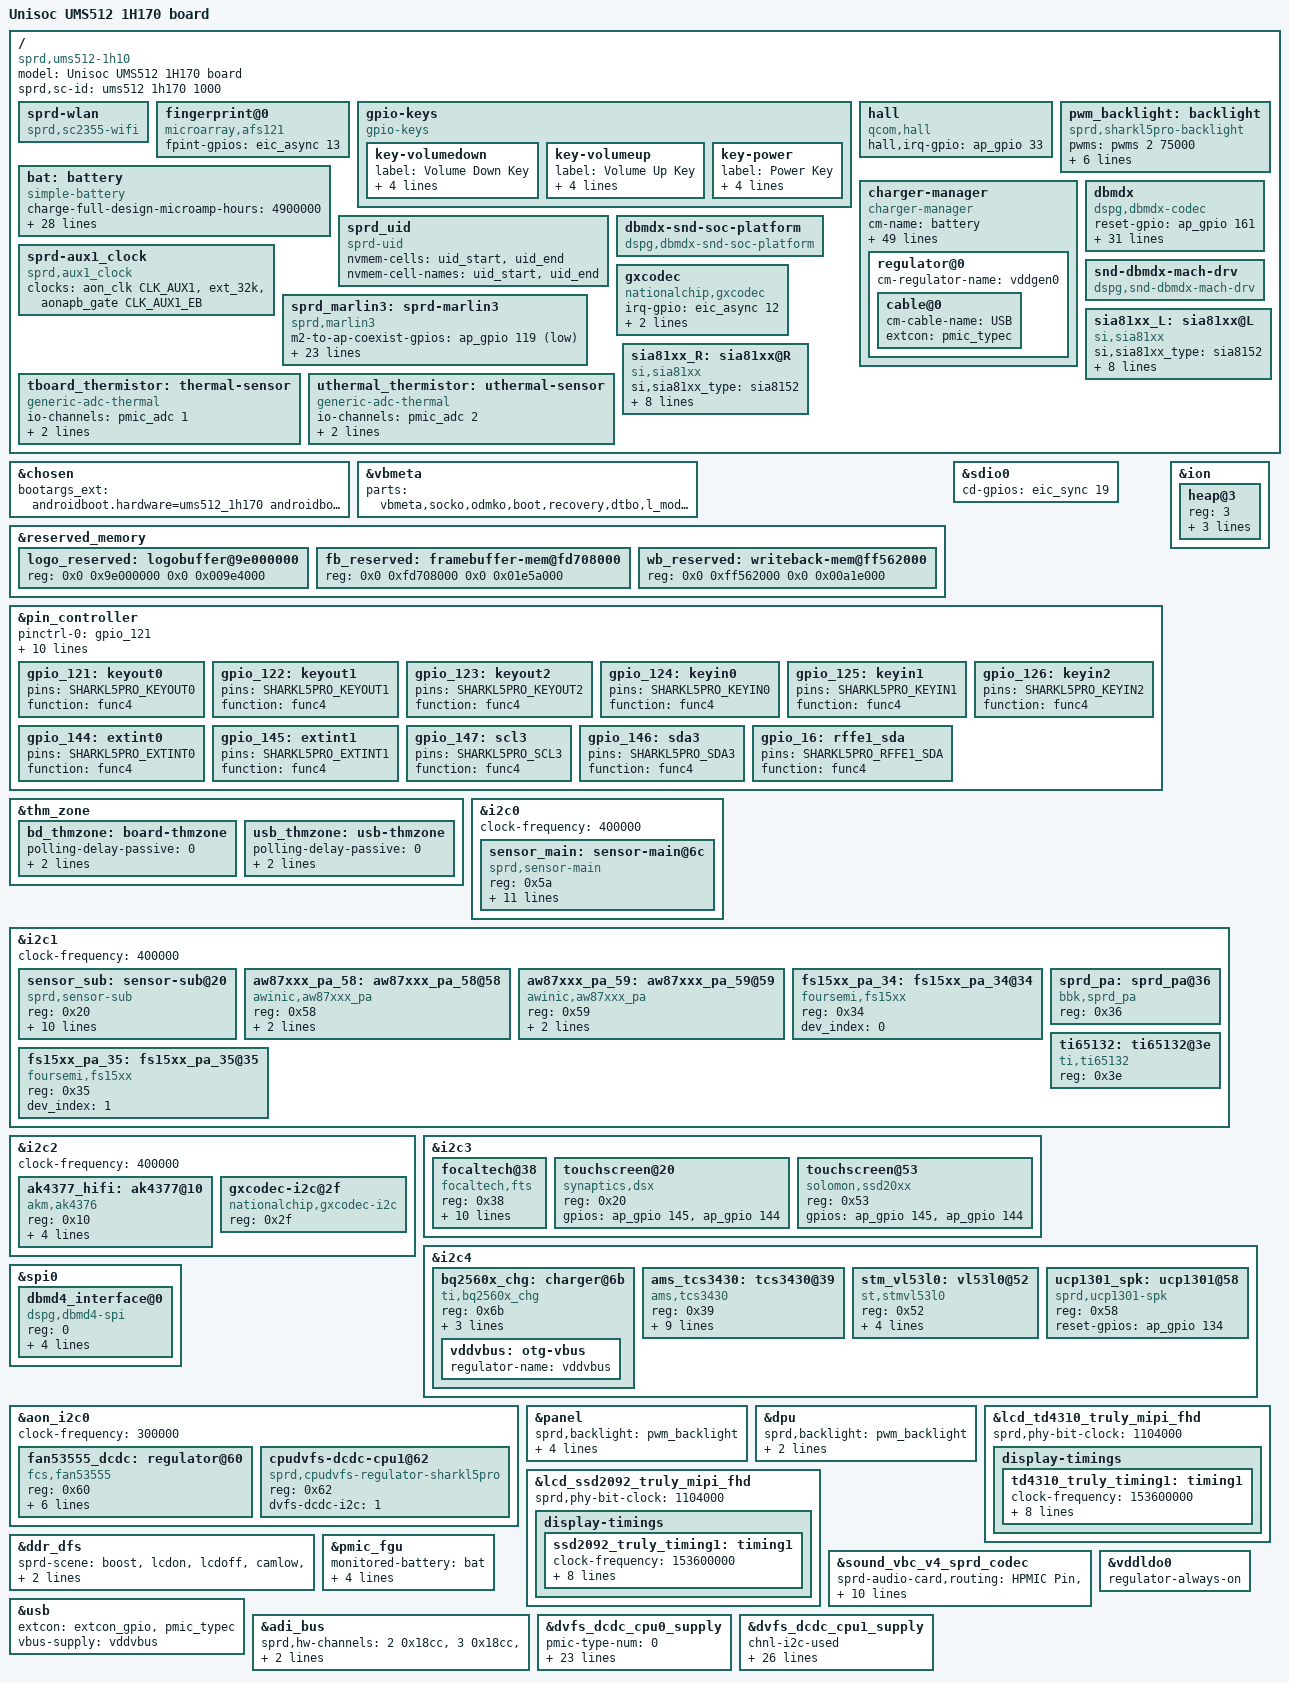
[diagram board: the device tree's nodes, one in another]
/*
 * EEBBK A3 (ums512_1h170) board overlay
 * -------------------------------------
 * Reconstructed from the factory DTBO overlay (dtbo partition, idx 2,
 * sc-id "ums512 1h170 1000") decompiled from the device, adapted to the
 * UNISOC 4.14.193 tree structure (labels per ums512.dtsi / ums512-mach.dtsi).
 * Values (battery, GPIOs, clocks, lcd panels) are verbatim from the factory
 * device tree. Kernel base: android_kernel_realme_ums512 (4.14.193).
 */
/dts-v1/;
/plugin/;

#include <dt-bindings/input/input.h>
#include <dt-bindings/gpio/gpio.h>
#include <dt-bindings/interrupt-controller/arm-gic.h>
#include <dt-bindings/clock/sprd,sharkl5pro-clk.h>
#include <dt-bindings/mfd/sprd,sc2730-regs.h>
#include <dt-bindings/mfd/sprd,sc2730-mask.h>
#include "lcd/lcd_ft8201ab_boe_mipi_fhd_bbk_H170.dtsi"
#include "lcd/lcd_ft8201ab_boe_mipi_fhd_bbk_H170.dtsi"
#include "lcd/lcd_td4310_truly_mipi_fhd.dtsi"
#include "lcd/lcd_ssd2092_truly_mipi_fhd.dtsi"
#include "lcd/lcd_dummy_mipi.dtsi"

/ {

	model = "Unisoc UMS512 1H170 board";
	compatible = "sprd,ums512-1h10";
	sprd,sc-id = "ums512 1h170 1000";

	fragment {
		target-path = "/";
		__overlay__ {
			sprd-wlan {
				compatible = "sprd,sc2355-wifi";
			};

			fingerprint@0 {
				compatible = "microarray,afs121";
				fpint-gpios = <&eic_async 13 0>;
			};

			gpio-keys {
				compatible = "gpio-keys";

				key-volumedown {
					label = "Volume Down Key";
					linux,code = <KEY_VOLUMEDOWN>;
					gpios = <&ap_gpio 124 GPIO_ACTIVE_LOW>;
					debounce-interval = <2>;
					wakeup-source;
				};

				key-volumeup {
					label = "Volume Up Key";
					linux,code = <KEY_VOLUMEUP>;
					gpios = <&pmic_eic 4 GPIO_ACTIVE_HIGH>;
					debounce-interval = <2>;
					wakeup-source;
				};

				key-power {
					label = "Power Key";
					linux,code = <KEY_POWER>;
					gpios = <&pmic_eic 1 GPIO_ACTIVE_LOW>;
					debounce-interval = <2>;
					wakeup-source;
				};
			};

			hall {
				compatible = "qcom,hall";
				hall,irq-gpio = <&ap_gpio 33 2>;
			};

			pwm_backlight: backlight {
				compatible = "sprd,sharkl5pro-backlight";
				pwms = <&pwms 2 75000>;
				pwm-names = "backlight";
				sprd,max-brightness-level = <880>;
				default-brightness-level = <250>;
				sprd,brightness-scale = <1023>;
				brightness-levels = <
							  0   3   4   5   6   7
					  8   9  10  11  12  13  14  15  16  17
					 18  19  20  21  22  23  24  25  26  27
					 28  29  31  33  35  37  39  41  43  45
					 46  48  50  52  54  56  58  60  62  64
					 66  68  70  72  74  76  78  80  82  84
					 86  88  90  92  94  96  98 100 102 104
					106 108 110 112 114 116 118 120 122 124
					126 128 130 132 134 136 138 140 142 144
					146 148 150 152 154 156 158 160 162 164
					166 169 172 175 178 181 184 187 190 193
					196 199 202 205 208 211 214 217 220 223
					226 229 232 235 238 241 244 247 250 253
					256 259 262 265 268 271 274 277 280 283
					286 290 294 298 302 306 310 314 318 322
					326 330 334 338 342 346 350 354 358 362
					366 370 374 378 382 386 390 394 398 402
					406 410 414 418 422 426 430 434 438 442
					446 451 456 461 466 471 476 481 486 491
					496 501 506 511 516 521 526 531 536 541
					546 551 556 561 566 571 576 581 586 591
					596 601 606 611 616 621 626 631 636 641
					646 652 658 664 670 676 682 688 694 700
					706 712 718 724 730 736 742 748 754 760
					766 772 778 784 790 796 802 808 814 820
					826 832 838 844 850 856 862 868 874 880
				>;
			};

			bat: battery {
				compatible = "simple-battery";
				charge-full-design-microamp-hours = <4900000>;
				charge-term-current-microamp = <240000>;
				constant_charge_voltage_max_microvolt = <4423000>;
				factory-internal-resistance-micro-ohms = <134000>;
				voltage-min-design-microvolt = <3480000>;
				ocv-capacity-celsius = <25>;
				ocv-capacity-table-0 = <4386000 100>, <4329000 95>, <4274000 90>,
							<4217000 85>, <4160000 80>, <4106000 75>,
							<4055000 70>, <4008000 65>, <3964000 60>,
							<3905000 55>, <3866000 50>, <3840000 45>,
							<3818000 40>, <3800000 35>, <3784000 30>,
							<3766000 25>, <3744000 20>, <3719000 15>,
							<3690000 10>, <3679000 5>, <3460000 0>;
				voltage-temp-table = <1092500 800>, <984400 850>, <877900 900>,
						  <775600 950>, <679400 1000>, <591100 1050>,
						  <511400 1100>, <440700 1150>, <378500 1200>,
						  <324500 1250>, <278000 1300>, <238000 1350>,
						  <204000 1400>, <175000 1450>, <150300 1500>,
						  <129400 1550>, <111600 1600>, <96500 1650>;
				capacity-temp-table = <50 98>, <25 100>, <10 92>, <0 74>, <(-10) 65>, <(-20) 55>;
				resistance-temp-table = <50 74>, <25 100>, <10 168>, <0 380>, <(-10) 539>, <(-20) 750>;
				charge-sdp-current-microamp = <500000 500000>;
				charge-dcp-current-microamp = <2160000 2000000>;
				charge-cdp-current-microamp = <1150000 1150000>;
				charge-unknown-current-microamp = <2160000 2000000>;
			};

			charger-manager {
				compatible = "charger-manager";
				cm-name = "battery";
				cm-poll-mode = <2>;
				cm-poll-interval = <2000>;
				cm-battery-stat = <2>;

				cm-fullbatt-vchkdrop-ms = <30000>;
				cm-fullbatt-vchkdrop-volt = <60000>;
				cm-fullbatt-voltage = <4377750>;
				cm-fullbatt-current = <240000>;
				cm-fullbatt-capacity = <100>;

				cm-num-chargers = <1>;
				cm-chargers = "bq2560x_charger";
				cm-fuel-gauge = "sc27xx-fgu";

				/* in deci centigrade */
				cm-battery-cold = <200>;
				cm-battery-cold-in-minus;
				cm-battery-hot = <800>;
				cm-battery-temp-diff = <100>;

				/* Allow charging for 18hr */
				cm-charging-max = <64800000>;
				/* recovery charging after stop charging 45min */
				cm-discharging-max = <2700000>;

				/* the interval to feed charger watchdog */
				cm-wdt-interval = <60>;

				/* drop voltage in microVolts to allow shutdown */
				cm-shutdown-voltage = <3380000>;

				/* when 99% of the time is exceeded, it will be forced to 100% */
				cm-tickle-time-out = <1500>;

				/* how much time to allow capacity change */
				cm-one-cap-time = <30>;
				cm-thermal-zone = "board-thmzone";
				/* when the safe charging voltage is exceeded, stop charging */
				cm-charge-voltage-max = <6500000>;
				/* drop voltage in microVolts to restart charging */
				cm-charge-voltage-drop = <700000>;
				cm-dcp-jeita-temp-table = <1000 1010 0 4423000>, <1100 1110 1380000 4423000>,
					<1200 1210 1980000 4423000>, <1450 1440 2160000 4423000>,
					<1550 1540 1440000 4103000>;
				cm-sdp-jeita-temp-table = <1000 1010 0 4423000>, <1100 1110 500000 4423000>,
					<1200 1210 500000 4423000>, <1450 1440 500000 4423000>,
					<1550 1540 500000 4103000>;
				cm-cdp-jeita-temp-table = <1000 1010 0 4423000>, <1100 1110 1200000 4423000>,
					<1200 1210 1200000 4423000>, <1450 1440 1200000 4423000>,
					<1550 1540 1200000 4103000>;
				cm-unknown-jeita-temp-table = <1000 1010 0 4423000>, <1100 1110 1380000 4423000>,
					<1200 1210 1980000 4423000>, <1450 1440 2160000 4423000>,
					<1550 1540 1440000 4103000>;

				monitored-battery = <&bat>;
				fgu-capacity-track;

				cm-cap-remap-table = <1 2 3>, <2 3 2>, <98 99 2>, <99 100 3>;

				regulator@0 {
					cm-regulator-name = "vddgen0";
					cable@0 {
						cm-cable-name = "USB";
						extcon = <&pmic_typec>;
					};
				};
			};

			sprd_uid {
				compatible = "sprd-uid";
				nvmem-cells = <&uid_start>, <&uid_end>;
				nvmem-cell-names = "uid_start", "uid_end";
			};

			sprd-aux1_clock {
				compatible = "sprd,aux1_clock";
				clock-names = "clk_32k", "source", "enable";
				clocks = <&aon_clk CLK_AUX1>, <&ext_32k>,
					 <&aonapb_gate CLK_AUX1_EB>;
			};

			dbmdx {
				status = "okay";
				compatible = "dspg,dbmdx-codec";
				reset-gpio = <&ap_gpio 161 0>;
				sv-gpio = <&eic_async 12 0>;
				wakeup-gpio = <&ap_gpio 52 0>;
				auto_buffering = <1>;
				multi-interface-support = <1>;
				cd-interfaces = <7>;
				va-interfaces = <0 0 0 0>;
				feature-va;
				va-firmware-name = "dbmd4_va_fw.bin";
				va-config = <0x80000000 0x80000000 0x80290020 0x802210c0
					0x80330056 0x80091400 0x80158989 0x801b0020
					0x80230000 0x801a0011 0x80105000 0x8aab0040
					0x80410001 0x80000000 0x80000000 0x80000000>;
				va-speeds = <0 0x70800 0 0xea600 0 0x1e8480 0 0x493e00
					0 0x2dc6c0 0 0x493e00>;
				va-mic-config = <0xf051 0x1044 0x08>;
				va-mic-mode = <4>;
				analog_mic_analog_gain = <5>;
				master-clk-rate = <0x8000>;
				firmware_id = <0xdbd4>;
				use_gpio_for_wakeup = <1>;
				wakeup_set_value = <0>;
				auto_detection = <1>;
				detection_buffer_channels = <0>;
				min_samples_chunk_size = <0x80>;
				pcm_streaming_mode = <1>;
				boot_options = <0x200>;
				amodel_options = <4>;
				send_uevent_on_detection = <1>;
				send_uevent_after_buffering = <0>;
				detection_after_buffering = <0>;
				va_backlog_length = <0x6a4>;
				va_advanced_options = <0x1d>;
				va_passphrase_margins = <0x12c0000>;
			};

			dbmdx-snd-soc-platform {
				compatible = "dspg,dbmdx-snd-soc-platform";
			};

			snd-dbmdx-mach-drv {
				compatible = "dspg,snd-dbmdx-mach-drv";
			};

			gxcodec {
				compatible = "nationalchip,gxcodec";
				irq-gpio = <&eic_async 12 0>;
				power-gpio = <&ap_gpio 161 0>;
				vddcore-supply = <&vddrf1v25>;
			};

			sprd_marlin3: sprd-marlin3 {
				compatible = "sprd,marlin3";
				m2-to-ap-coexist-gpios = <&ap_gpio 119 GPIO_ACTIVE_LOW>;
				m2-wakeup-ap-gpios = <&ap_gpio 32 GPIO_ACTIVE_LOW>;
				permit-ap-send-gpios = <&ap_gpio 121 GPIO_ACTIVE_LOW>;
				reset-gpios = <&ap_gpio 97 GPIO_ACTIVE_LOW>;
				enable-gpios = <&ap_gpio 143 GPIO_ACTIVE_LOW>;
				m2-to-ap-irq-gpios = <&ap_gpio 96 GPIO_ACTIVE_LOW>;
				avdd12-supply = <&vddwcn>;
				avdd33-supply = <&vddwifipa>;
				dcxo18-supply = <&vddsim2>;

				clock-names = "clk_32k","source","enable";
				clocks = <&aon_clk CLK_AUX0>,
					 <&ext_32k>,
					 <&aonapb_gate CLK_AUX0_EB>;

				sdhci-name = <&sdio1>;
				sprd,btwf-file-name = "/dev/block/platform/soc/soc:ap-apb/71400000.sdio/by-name/wcnmodem";
				sprd,gnss-file-name = "/dev/block/platform/soc/soc:ap-apb/71400000.sdio/by-name/gnssmodem";
				adma-tx;
				adma-rx;
				/*
				 * bound parameter:
				 * [0]:addr offset, [1]:mask, [2]:unboundval, [3]:boundval
				 */
				avdd12-parent-bound-chip = <REG_ANA_SLP_DCDC_PD_CTRL MASK_ANA_SLP_DCDCGEN1_PD_EN 0x0 MASK_ANA_SLP_DCDCGEN1_PD_EN>;
				avdd12-bound-wbreq = <REG_ANA_LDO_XTL_EN10 MASK_ANA_LDO_VDDWCN_EXT_XTL3_EN 0x0 MASK_ANA_LDO_VDDWCN_EXT_XTL3_EN>;
				avdd33-bound-wbreq = <REG_ANA_LDO_XTL_EN11 MASK_ANA_LDO_VDDWIFIPA_EXT_XTL3_EN 0x0 MASK_ANA_LDO_VDDWIFIPA_EXT_XTL3_EN>;
			};

			tboard_thermistor: thermal-sensor {
				compatible = "generic-adc-thermal";
				#thermal-sensor-cells = <0>;
				io-channels = <&pmic_adc 1>;
				io-channel-names = "sensor-channel";
				temperature-lookup-table = <    (-39742) 1260
								(-29777) 1213
								(-19480) 1146
								(-4679) 1005
								10110 824
								24805 632
								44922 409
								54903 322
								64895 252
								74884 197
								84883 154
								94883 121
								104880 98
								114889 76
								124872 61 >;
			};

			uthermal_thermistor: uthermal-sensor {
				compatible = "generic-adc-thermal";
				#thermal-sensor-cells = <0>;
				io-channels = <&pmic_adc 2>;
				io-channel-names = "sensor-channel";
				temperature-lookup-table = <    (-39742) 1330
								(-29777) 1327
								(-19480) 1321
								(-4679) 1302
								10110 1266
								24805 1200
								44922 1049
								54903 946
								64895 830
								74884 709
								84883 592
								94883 485
								104880 391
								114889 313
								124872 249 >;
			};

			/* smart speaker amps (SIA8152) */
			sia81xx_L: sia81xx@L {
				compatible = "si,sia81xx";
				si,sia81xx_type = "sia8152";
				si,sia81xx_disable_pin = <1>;
				timer_task_hdl = <0>;
				channel_num = <0>;
				owi_mode = <1>;
				en_x_filter = <0>;
				en_dynamic_updata_vdd = <1>;
				en_dynamic_updata_pvdd = <1>;
				dynamic_updata_vdd_port = <2>;
			};

			sia81xx_R: sia81xx@R {
				compatible = "si,sia81xx";
				si,sia81xx_type = "sia8152";
				si,sia81xx_disable_pin = <1>;
				timer_task_hdl = <0>;
				channel_num = <1>;
				owi_mode = <1>;
				en_x_filter = <0>;
				en_dynamic_updata_vdd = <1>;
				en_dynamic_updata_pvdd = <1>;
				dynamic_updata_vdd_port = <2>;
			};
		};
	};
};

&chosen {
	bootargs_ext = "androidboot.hardware=ums512_1h170 androidboot.dtbo_idx=0";
};

&vbmeta {
	parts = "vbmeta,socko,odmko,boot,recovery,dtbo,l_modem,pm_sys,l_ldsp,l_gdsp,l_agdsp,l_cdsp";
};

&reserved_memory {

	logo_reserved: logobuffer@9e000000{
		reg = <0x0 0x9e000000 0x0 0x009e4000>;
	};

	fb_reserved: framebuffer-mem@fd708000 {
		reg = <0x0 0xfd708000 0x0 0x01e5a000>;
	};

	wb_reserved: writeback-mem@ff562000 {
		reg = <0x0 0xff562000 0x0 0x00a1e000>;
	};

};

&sdio0 {
	cd-gpios = <&eic_sync 19 GPIO_ACTIVE_HIGH>;
};

&pin_controller {
	pinctrl-names =
	/* keyout0 ~ keyout2 */
	"gpio_121", "gpio_122", "gpio_123",
	/* keyin0 ~ keyin2 */
	"gpio_124", "gpio_125", "gpio_126",
	/* extint0, extint1, scl3, sda3, sda */
	"gpio_144", "gpio_145", "gpio_146", "gpio_147", "gpio_16";

	pinctrl-0 = <&gpio_121>;
	pinctrl-1 = <&gpio_122>;
	pinctrl-2 = <&gpio_123>;
	pinctrl-3 = <&gpio_124>;
	pinctrl-4 = <&gpio_125>;
	pinctrl-5 = <&gpio_126>;
	pinctrl-6 = <&gpio_144>;
	pinctrl-7 = <&gpio_145>;
	pinctrl-8 = <&gpio_146>;
	pinctrl-9 = <&gpio_147>;
	pinctrl-10 = <&gpio_16>;

	gpio_121: keyout0 {
		pins = "SHARKL5PRO_KEYOUT0";
		function = "func4";
	};

	gpio_122: keyout1 {
		pins = "SHARKL5PRO_KEYOUT1";
		function = "func4";
	};

	gpio_123: keyout2 {
		pins = "SHARKL5PRO_KEYOUT2";
		function = "func4";
	};

	gpio_124: keyin0 {
		pins = "SHARKL5PRO_KEYIN0";
		function = "func4";
	};

	gpio_125: keyin1 {
		pins = "SHARKL5PRO_KEYIN1";
		function = "func4";
	};

	gpio_126: keyin2 {
		pins = "SHARKL5PRO_KEYIN2";
		function = "func4";
	};

	gpio_144: extint0 {
		pins = "SHARKL5PRO_EXTINT0";
		function = "func4";
	};

	gpio_145: extint1 {
		pins = "SHARKL5PRO_EXTINT1";
		function = "func4";
	};

	gpio_147: scl3 {
		pins = "SHARKL5PRO_SCL3";
		function = "func4";
	};

	gpio_146: sda3 {
		pins = "SHARKL5PRO_SDA3";
		function = "func4";
	};

	gpio_16: rffe1_sda {
		pins = "SHARKL5PRO_RFFE1_SDA";
		function = "func4";
	};
};

&thm_zone {
	bd_thmzone: board-thmzone {
		polling-delay-passive = <0>;
		polling-delay = <0>;
		thermal-sensors = <&tboard_thermistor>;
	};

	usb_thmzone: usb-thmzone {
		polling-delay-passive = <0>;
		polling-delay = <0>;
		thermal-sensors = <&uthermal_thermistor>;
	};
};

&ion {
	heap@3 {
		reg = <3>;
		label = "carveout_fb";
		type = <2>;
		memory-region = <&fb_reserved>;
	};
};

&i2c0 {
	status = "okay";
	clock-frequency = <400000>;

	sensor_main: sensor-main@6c {
		compatible = "sprd,sensor-main";
		reg = <0x5a>;
		clock-names = "clk_src","sensor_eb",
			"clk_96m","clk_76m8",
			"clk_48m","clk_26m";
		clocks = <&mm_clk CLK_SENSOR0>,<&mm_gate CLK_MM_SENSOR0_EB>,
				<&pll2 CLK_TWPLL_96M>,<&pll2 CLK_TWPLL_76M8>,
				<&pll2 CLK_TWPLL_48M>,<&ext_26m>;
		vddio-supply = <&vddcamio>;
		vddcama-supply = <&vddcama0>;
		vddcamd-supply = <&vddcamd1>;
		vddcammot-supply = <&vddcammot>;
		reset-gpios = <&ap_gpio 45 0>;
		sprd,phyid = <0>;
		csi = <&csi0>;
	};
};

&i2c1 {
	status = "okay";
	clock-frequency = <400000>;

	sensor_sub: sensor-sub@20 {
		compatible = "sprd,sensor-sub";
		reg = <0x20>;
		clock-names = "clk_src","sensor_eb",
			"clk_96m","clk_76m8",
			"clk_48m","clk_26m";
		clocks = <&mm_clk CLK_SENSOR1>,<&mm_gate CLK_MM_SENSOR1_EB>,
				<&pll2 CLK_TWPLL_96M>,<&pll2 CLK_TWPLL_76M8>,
				<&pll2 CLK_TWPLL_48M>,<&ext_26m>;
		vddio-supply = <&vddcamio>;
		vddcama-supply = <&vddcama0>;
		vddcamd-supply = <&vddcamd0>;
		reset-gpios = <&ap_gpio 41 0>;
		sprd,phyid = <1>;
		csi = <&csi0>;
	};

	/* smart speaker amps — L/R (AW87xxx / SIA8152), on i2c1 per factory DT */
	aw87xxx_pa_58: aw87xxx_pa_58@58 {
		compatible = "awinic,aw87xxx_pa";
		reg = <0x58>;
		si,sia81xx-dev = <&sia81xx_L>;
		dev_index = <0>;
		status = "okay";
	};

	aw87xxx_pa_59: aw87xxx_pa_59@59 {
		compatible = "awinic,aw87xxx_pa";
		reg = <0x59>;
		si,sia81xx-dev = <&sia81xx_R>;
		dev_index = <1>;
		status = "okay";
	};

	fs15xx_pa_34: fs15xx_pa_34@34 {
		compatible = "foursemi,fs15xx";
		reg = <0x34>;
		dev_index = <0>;
		status = "okay";
	};

	fs15xx_pa_35: fs15xx_pa_35@35 {
		compatible = "foursemi,fs15xx";
		reg = <0x35>;
		dev_index = <1>;
		status = "okay";
	};

	sprd_pa: sprd_pa@36 {
		compatible = "bbk,sprd_pa";
		reg = <0x36>;
		status = "okay";
	};

	ti65132: ti65132@3e {
		compatible = "ti,ti65132";
		reg = <0x3e>;
	};
};

&i2c2 {
	status = "okay";
	clock-frequency = <400000>;

	ak4377_hifi: ak4377@10 {
		compatible = "akm,ak4376";
		reg = <0x10>;
		#sound-dai-cells = <1>;
		sprd,vddldo1-voltage = <1800000>;
		ak4377,pdn-gpio = <&ap_gpio 116 GPIO_ACTIVE_HIGH>;

		clock-names = "clk_48M", "source", "enable";
		clocks = <&aon_clk CLK_AUX1>,
			 <&pll2 CLK_TWPLL_19M2>,
			 <&aonapb_gate CLK_AUX1_EB>;
	};

	gxcodec-i2c@2f {
		compatible = "nationalchip,gxcodec-i2c";
		reg = <0x2f>;
	};

};

&i2c3 {
	status = "okay";

	/* FocalTech FTS — the active touch controller on this board (i2c-3 @ 0x38) */
	focaltech@38 {
		compatible = "focaltech,fts";
		reg = <0x38>;
		status = "okay";
		focaltech,irq-gpio = <&eic_async 0 0>;
		focaltech,irq-flags = <2>;
		focaltech,reset-gpio = <&ap_gpio 145 0>;
		focaltech,max-touch-number = <10>;
		focaltech,display-coords = <0 0 1279 1751>;
		tpd-filter-enable = <0>;
		tpd-filter-pixel-density = <161>;
		tpd-filter-custom-prameters = <0 0 0 0 0 0 0 0 0 0 0 0>;
		tpd-filter-custom-speed = <0 0 0>;
	};

	/* alternate touch drivers present on the same bus (hardware absent) */
	touchscreen@20 {
		compatible = "synaptics,dsx";
		reg = <0x20>;
		gpios = <&ap_gpio 145 GPIO_ACTIVE_HIGH
			&ap_gpio 144 GPIO_ACTIVE_HIGH>;
	};

	touchscreen@53 {
		compatible = "solomon,ssd20xx";
		reg = <0x53>;
		gpios = <&ap_gpio 145 GPIO_ACTIVE_HIGH
			&ap_gpio 144 GPIO_ACTIVE_HIGH>;
	};
};

&i2c4 {
	status = "okay";

	bq2560x_chg: charger@6b {
		compatible = "ti,bq2560x_chg";
		reg = <0x6b>;
		phys = <&hsphy>;
		monitored-battery = <&bat>;
		extcon = <&extcon_gpio>;
		vddvbus: otg-vbus {
			regulator-name = "vddvbus";
		};
	};

	ams_tcs3430: tcs3430@39 {
		compatible = "ams,tcs3430";
		reg = <0x39>;
		als_name = "ams_als";
		persist = <0>;
		als_time_ms = <100>;
		als_gain = <64>;
		int_config = <0>;
		als_can_wake = <1>;
		irq_gpios = <112>;
		interrupt-parent = <&ap_gpio>;
		interrupts = <112 IRQ_TYPE_LEVEL_LOW>;
	};

	stm_vl53l0: vl53l0@52 {
		compatible = "st,stmvl53l0";
		reg = <0x52>;
		reset_gpios = <86>;
		irq_gpios = <87>;
		interrupt-parent = <&ap_gpio>;
		interrupts = <87 IRQ_TYPE_LEVEL_LOW>;
	};

	/* speaker amplifier */
	ucp1301_spk: ucp1301@58 {
		compatible = "sprd,ucp1301-spk";
		reg = <0x58>;
		reset-gpios = <&ap_gpio 134 0>;
		#sound-dai-cells = <1>;
	};
};

&spi0 {
	status = "okay";

	dbmd4_interface@0 {
		compatible = "dspg,dbmd4-spi";
		reg = <0>;
		spi-max-frequency = <12000000>;
		read-chunk-size = <0x2000>;
		write-chunk-size = <0x40000>;
		dma_min_buffer_size = <0>;
	};
};

&aon_i2c0 {
	status = "okay";
	clock-frequency = <300000>;

	fan53555_dcdc: regulator@60 {
		compatible = "fcs,fan53555";
		reg = <0x60>;
		regulator-name = "fan53555";
		regulator-min-microvolt = <600000>;
		regulator-max-microvolt = <1230000>;
		regulator-ramp-delay = <64000>;
		regulator-always-on;
		fcs,suspend-voltage-selector = <1>;
	};

	/* A virtual i2c device */
	cpudvfs-dcdc-cpu1@62{
		compatible = "sprd,cpudvfs-regulator-sharkl5pro";
		reg = <0x62>;
		dvfs-dcdc-i2c = <1>;
	};
};

&panel {
	sprd,backlight = <&pwm_backlight>;
	power-supply = <&vddldo1>;
	avdd-gpio = <&ap_gpio 139 GPIO_ACTIVE_HIGH>;
	avee-gpio = <&ap_gpio 137 GPIO_ACTIVE_HIGH>;
	reset-gpio = <&ap_gpio 50 GPIO_ACTIVE_HIGH>;
};

&dpu {
	sprd,backlight = <&pwm_backlight>;
	sprd,wb-memory = <&wb_reserved>;
	sprd,logo-memory = <&logo_reserved>;
};

&lcd_td4310_truly_mipi_fhd {
	sprd,phy-bit-clock = <1104000>;  /* kbps */

	display-timings {
		td4310_truly_timing1: timing1 {
			clock-frequency = <153600000>;
			hactive = <720>;
			vactive = <1440>;
			hback-porch = <20>;
			hfront-porch = <50>;
			vback-porch = <28>;
			vfront-porch = <4>;
			hsync-len = <2>;
			vsync-len = <2>;
		};
	};
};

&lcd_ssd2092_truly_mipi_fhd {
	sprd,phy-bit-clock = <1104000>;  /* kbps */

	display-timings {
		ssd2092_truly_timing1: timing1 {
			clock-frequency = <153600000>;
			hactive = <720>;
			vactive = <1440>;
			hback-porch = <20>;
			hfront-porch = <20>;
			vback-porch = <43>;
			vfront-porch = <76>;
			hsync-len = <4>;
			vsync-len = <1>;
		};
	};
};

&ddr_dfs {
	sprd-scene = "boost", "lcdon", "lcdoff", "camlow",
		"camhigh", "camveryhigh", "faceid";
	sprd-freq = <1333 768 256 384 512 0xbacd 1333>;
};

&sound_vbc_v4_sprd_codec {
	status = "okay";
	sprd-audio-card,routing =
		"HPMIC Pin", "HP Mic Jack",
		"MIC Pin", "Mic Jack",
		"MIC2 Pin", "Aux Mic Jack",
		"HeadPhone Jack", "HP Pin",
		"Ext Spk", "HP Pin",
		"Ext Spk1", "HP Pin",
		"Ext Spk", "SPK Pin",
		"Ext Spk1", "SPK Pin",
		"Ext Ear", "EAR Pin",
		"Ext Ear", "SPK Pin",
		"Ext Ear", "HP Pin";
	/* external smart PA control (AW87xxx) */
	sprd,spk-ext-pa-info = <0 1 4 0 2 1 4 1>;
	/* SIA81xx integration (driver optional; harmless if absent) */
	si,sia81xx-max-num = <2>;
	si,sia81xx-aux-devs = <&sia81xx_L>, <&sia81xx_R>;
	si,sia81xx-aux-devs-prefix = "SpkrLeft", "SpkrRight";
};

&pmic_fgu {
	monitored-battery = <&bat>;
	sprd,calib-resistance-real = <10000>;
	sprd,calib-resistance-spec = <20000>;
	first-calib-voltage = <3690000>;
	first-calib-capacity = <100>;
};

&usb {
	extcon = <&extcon_gpio>, <&pmic_typec>;
	vbus-supply = <&vddvbus>;
};

&vddldo0 {
	regulator-always-on;
};

&adi_bus {
	sprd,hw-channels = <2 0x18cc>, <3 0x18cc>, <13 0x1854>, <15 0x1874>,
			 <17 0x1844>,<19 0x1844>, <21 0x1864>, <30 0x1820>,
			 <35 0x19b8>, <39 0x19ac>;
};

&dvfs_dcdc_cpu0_supply {
	pmic-type-num = <0>;
	slew-rate = <9375>; /* 9375uV/us */
	top-dvfs-adi-state = <0x70 0 0xf>;
	voltage-grade-num = <7>;
	voltage-grade = <0 0xf0 0xf4 0 0x1ff>,
		<1 0xf0 0xf4 9 0x1ff>,
		<2 0x100 0xf4 18 0x1ff>,
		<3 0x110 0xf8 0 0x1ff>,
		<4 0x120 0xf8 9 0x1ff>,
		<5 0x130 0xf8 18 0x1ff>,
		<6 0x140 0xfc 0 0x1ff>;
	voltage-up-delay = <50 0x58 0 0xffff 0x600>,
		<100 0x58 16 0xffff 0xa00>,
		<150 0x54 0 0xffff 0xf00>,
		<200 0x54 16 0xffff 0x1400>,
		<250 0x50 0 0xffff 0x1900>,
		<300 0x50 16 0xffff 0x1e00>,
		<350 0x110 0 0xffff 0x2300>;
	voltage-down-delay = <50 0x64 0 0xffff 0x600>,
		<100 0x64 16 0xffff 0xa00>,
		<150 0x60 0 0xffff 0xf00>,
		<200 0x60 16 0xffff 0x1400>,
		<250 0x5c 0 0xffff 0x1900>,
		<300 0x5c 16 0xffff 0x1e00>,
		<350 0x114 0 0xffff 0x2300>;
	tuning-latency-us = <0>;
	chnl-in-i2c = <0>;
};

&dvfs_dcdc_cpu1_supply {
	chnl-i2c-used;
	third-pmic-used;
	pmic-type-num = <2>;
	slew-rate = <4000>; /* 4000uV/us */
	supply-type-sel = <0x120 0 1>;
	top-dvfs-i2c-state = <0x9c 4 0xf>;
	voltage-grade-num = <6>;
	voltage-grade = <0 0x0f 0x12c 0 0x7f>,
		<1 0x14 0x12c 7 0x7f>,
		<2 0x19 0x12c 14 0x7f>,
		<3 0x1e 0x12c 21 0x7f>,
		<4 0x23 0x130 0 0x7f>,
		<5 0x28 0x130 7 0x7f>;
	voltage-up-delay = <50 0x84 0 0xffff 0x1600>,
		<100 0x84 16 0xffff 0x1a00>,
		<150 0x80 0 0xffff 0x1f00>,
		<200 0x80 16 0xffff 0x2400>,
		<250 0x7c 0 0xffff 0x2900>,
		<300 0x7c 16 0xffff 0x2e00>,
		<350 0x118 0 0xffff 0x3300>;
	voltage-down-delay = <50 0x90 0 0xffff 0x600>,
		<100 0x90 16 0xffff 0xa00>,
		<150 0x8c 0 0xffff 0xf00>,
		<200 0x8c 16 0xffff 0x1400>,
		<250 0x88 0 0xffff 0x1900>,
		<300 0x88 16 0xffff 0x1e00>,
		<350 0x11c 0 0xffff 0x2300>;
	tuning-latency-us = <0>;
	chnl-in-i2c = <1>;
};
